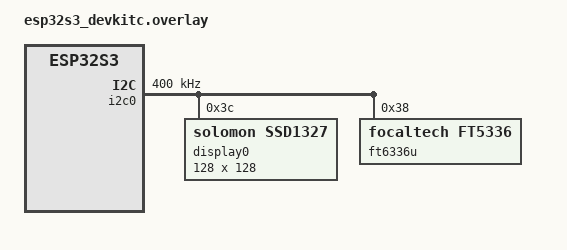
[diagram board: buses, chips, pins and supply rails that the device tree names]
/* Auto-generated by @typecad/framework-zephyr from typecad-hal.config.ts. */
/* Enables peripherals the program uses. West merges this over the board DT. */

&pinctrl {
    i2c0_display: i2c0_display {
        group1 {
            pinmux = <I2C0_SDA_GPIO17>, <I2C0_SCL_GPIO16>;
            bias-pull-up;
            drive-open-drain;
        };
    };
};

&i2c0 {
    status = "okay";
    clock-frequency = <400000>;
    pinctrl-0 = <&i2c0_display>;
    pinctrl-names = "default";
    display0: ssd1327@3c {
        compatible = "solomon,ssd1327";
        reg = <0x3c>;
        width = <128>;
        height = <128>;
        prechargep = <0x22>;
        oscillator-freq = <0x00>;
        display-offset = <0>;
        start-line = <0>;
        multiplex-ratio = <127>;
        remap-value = <0x51>;
        phase-length = <0x1f>;
    };
};

&i2c0 {
    status = "okay";
    ft6336u: ft6336u@38 {
        compatible = "focaltech,ft5336";
        reg = <0x38>;
        swapped-x-y;
    };
};
